VERSION "0.0.12.2"

NS_ :

BS_:

BU_: InstrumentCluster DCU
VAL_TABLE_ DisplayUserInformationTbl 3 "Not Available" 2 "Reserved" 1 "OK" 0 "NOK" ;
VAL_TABLE_ ChargingPortCommandTable 3 "Unknown" 2 "Reserved" 1 "Pressed" 0 "Released" ;
VAL_TABLE_ panicAlertFleetReq_table 3 "NotAvailable" 2 "Reserved" 1 "Panic Alert Requested" 0 "Not requested" ;
VAL_TABLE_ touchpointPanicAlertStatus_Table 3 "Exterior Touchpoints only" 2 "Interior Touchpoints only" 1 "All touchpoints" 0 "No alert" ;
VAL_TABLE_ panicAlertCancelReq_table 3 "NotAvailable" 2 "Reserved" 1 "Panic Alert Canceled" 0 "Not requested" ;
VAL_TABLE_ RouteAssigned_table 3 "Not available" 1 "Assigned" 0 "NotAssigned" ;
VAL_TABLE_ stopRequestStatus_table 10 "Door 3 Open" 9 "Door 2 Open" 8 "Door 1 Open" 7 "Door 3 Requested" 6 "Door 2 Requested" 5 "Door 1 Requested" 4 "Stop Completed" 3 "Stop Reached" 2 "Wheelchair Stop Requested" 1 "Bell Pusher Stop Requested" 0 "Not Requested" ;
VAL_TABLE_ CompressorFrozenStateTable 3 "NA" 1 "FROZEN" 0 "NORMAL" ;
VAL_TABLE_ CompressorState 3 "NA" 1 "ERROR" 0 "OK" ;
VAL_TABLE_ CommLostTable 3 "NA" 1 "Connection lost" 0 "OK" ;
VAL_TABLE_ ParkAssistAuto 3 "Not available" 1 "Requested" 0 "NotRequested" ;
VAL_TABLE_ RouteAssigned 3 "Not available" 1 "Assigned" 0 "NotAssigned" ;
VAL_TABLE_ CHRG_ReqTable 3 "Reserve" 2 "Stop charging" 1 "Immediate charging required" 0 "No request" ;
VAL_TABLE_ vt_TMSPumpControlMode 21 "NA" 2 "ParkMode" 1 "ChargeMode" 0 "DriveMode" ;
VAL_TABLE_ vtHVHeaterTempSP 3 "NA" 2 "TempSP2" 1 "TempSP1" 0 "NA1" ;
VAL_TABLE_ ChargeFaultState 4 "NEVER_ENABLE" 3 "FAULT_DELAY_BEFORE_EN" 2 "IGN_DISABLE" 1 "FAULT_DELAY_BEFORE_DIS" 0 "NO_FAULT" ;
VAL_TABLE_ ChargeOverride 3 "ChargingFault" 2 "ChargeAcOverrideEn" 1 "ChargeChademoOverrideEn" 0 "ChargeOverrideDis" ;
VAL_TABLE_ LvOverideStatus 3 "LvOverrideEn" 2 "LvOverrideEn_5minWait" 1 "LvThrCheckHVSock" 0 "LvOverideDis" ;
VAL_TABLE_ HVHeterPWMCMD_t 15 "NA" 13 "STANDBY1" 12 "OVERHEAT_UNLOCK" 11 "P8" 10 "P7" 9 "P6" 8 "P5" 7 "P4" 6 "P3" 5 "P2" 4 "P1" 3 "TEMP_SP2" 2 "TEMP_SP1" 1 "STANDBY" 0 "OFF" ;
VAL_TABLE_ HVHeaterPWMSTAT_t 15 "NA" 13 "LOCKED_PERM" 12 "LOCKED_OVERHEAT" 11 "LOCKED_TEMPOR" 10 "Ta75_PaSP" 9 "Tb75_PaSP" 8 "Tb40_PaSP" 7 "Tb0_PaSP" 6 "Ta75_PbSP" 5 "Tb75_PbSP" 4 "Tb40_PbSP" 3 "Tb0_PbSP" 2 "SP2" 1 "SP1" 0 "OFF" ;
VAL_TABLE_ HVDrStat_t 11 "ERRCHANGESP" 10 "HV_POWER_PROBLEM" 15 "NA" 9 "ERROR" 8 "FLOWNOTREADY" 7 "LOCKED_PERM" 6 "LOCKED_OVERHEAT" 5 "LOCKED_TEMPOR" 4 "SP_Request" 3 "SP_above" 2 "SP_below" 1 "STANDBY" 0 "OFF" ;
VAL_TABLE_ CabinBlowDirectionTbl 7 "NA" 0 "Reserved" 4 "Take_no_Action" 3 "Down" 2 "Med" 1 "Up" ;
VAL_TABLE_ vAction_t 3 "va_Take_no_action" 2 "va_Reserved" 1 "va_On" 0 "va_Off" ;
VAL_TABLE_ vtEnergyMode 7 "Not Available" 1 "RangeExtender" 0 "PureElectric" ;
VAL_TABLE_ vtOnOff 3 "Not available" 2 "Error" 1 "On" 0 "Off" ;

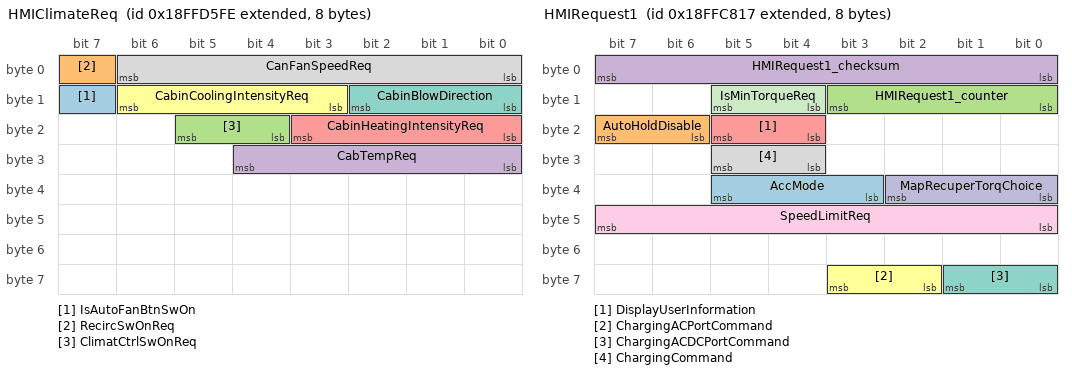
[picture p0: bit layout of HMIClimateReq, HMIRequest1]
BO_ 2566903294 HMIClimateReq: 8 Vector__XXX
 SG_ IsAutoFanBtnSwOn : 15|1@1+ (1,0) [0|0] "" Vector__XXX
 SG_ RecircSwOnReq : 7|1@1+ (1,0) [0|0] "" Vector__XXX
 SG_ ClimatCtrlSwOnReq : 20|2@1+ (1,0) [0|0] "" Vector__XXX
 SG_ CabTempReq : 24|5@1+ (1,0) [0|0] "" Vector__XXX
 SG_ CabinHeatingIntensityReq : 16|4@1+ (1,0) [0|0] "" Vector__XXX
 SG_ CabinCoolingIntensityReq : 11|4@1+ (1,0) [0|0] "" Vector__XXX
 SG_ CabinBlowDirection : 8|3@1+ (1,0) [0|0] "" Vector__XXX
 SG_ CanFanSpeedReq : 0|7@1+ (1,0) [0|0] "" Vector__XXX

BO_ 2381845271 STOPREQ: 8 Vector__XXX
 SG_ stopRequestStatus : 0|4@1+ (1,0) [0|15] "" Vector__XXX

BO_ 2566899735 HMIRequest1: 8 InstrumentCluster
 SG_ AccMode : 35|3@1+ (1,0) [0|7] "" Vector__XXX
 SG_ AutoHoldDisable : 22|2@1+ (1,0) [0|3] "" Vector__XXX
 SG_ HMIRequest1_counter : 8|4@1+ (1,0) [0|14] "" Vector__XXX
 SG_ HMIRequest1_checksum : 0|8@1+ (1,0) [0|255] "" Vector__XXX
 SG_ DisplayUserInformation : 20|2@1+ (1,0) [0|3] "" Vector__XXX
 SG_ ChargingACPortCommand : 58|2@1+ (1,0) [0|3] "" Vector__XXX
 SG_ ChargingACDCPortCommand : 56|2@1+ (1,0) [0|3] "" Vector__XXX
 SG_ ChargingCommand : 28|2@1+ (1,0) [0|3] "" Vector__XXX
 SG_ SpeedLimitReq : 40|8@1+ (1,0) [0|0] "kph" Vector__XXX
 SG_ MapRecuperTorqChoice : 32|3@1+ (1,0) [0|0] "" Vector__XXX
 SG_ IsMinTorqueReq : 12|2@1+ (1,0) [0|3] "" Vector__XXX

BO_ 2583184638 HMIPlatform_Info: 8 Vector__XXX
 SG_ ManualLevelling_Value : 0|8@1+ (1,0) [0|100] "" Vector__XXX

CM_ BO_ 2566899735 "DataID 0xFC8";
CM_ SG_ 2566899735 HMIRequest1_counter "counter signal for E2E protection";
CM_ SG_ 2566899735 HMIRequest1_checksum "Checksum signal for E2E protection";
CM_ SG_ 2566899735 MapRecuperTorqChoice "Choice of recuperation torque map:1,2,3... - select # of Map";
CM_ SG_ 2566899735 IsMinTorqueReq "Define Is minimal torque required when pedal is not depressed";
CM_ BO_ 2583184638 "The message contains the manual request for headlamps height  from HMI
HDLGHTLVL 1.0.0->ManualLevellingHeadlamps";
BA_DEF_  "DBName" STRING ;
BA_DEF_ SG_  "SigType" ENUM  "Default","Range","RangeSigned","ASCII","Discrete","Control","ReferencePGN","DTC","StringDelimiter","StringLength","StringLengthControl","MessageCounter","MessageChecksum";
BA_DEF_ SG_  "GenSigStartValue" INT 0 2147483647;
BA_DEF_ SG_  "GenSigSendType" ENUM  "Cyclic","OnWrite","OnWriteWithRepetition","OnChange","OnChangeWithRepetition","IfActive","IfActiveWithRepetition","NoSigSendType";
BA_DEF_ SG_  "GenSigILSupport" ENUM  "No","Yes";
BA_DEF_ SG_  "GenSigEVName" STRING ;
BA_DEF_ BO_  "GenMsgILSupport" ENUM  "No","Yes";
BA_DEF_ BO_  "GenMsgRequestable" INT 0 1;
BA_DEF_ BO_  "GenMsgSendType" ENUM  "cyclic","NotUsed","NotUsed","NotUsed","NotUsed","NotUsed","NotUsed","IfActive","noMsgSendType";
BA_DEF_ BO_  "VFrameFormat" ENUM  "StandardCAN","ExtendedCAN","reserved","J1939PG";
BA_DEF_ BO_  "GenMsgCycleTime" INT 0 3600000;
BA_DEF_ BU_  "NmStationAddress" INT 0 255;
BA_DEF_  "SAE_J1939_DA_SpecVersion" STRING ;
BA_DEF_  "SAE_J1939_81_SpecVersion" STRING ;
BA_DEF_  "DatabaseVersion" STRING ;
BA_DEF_  "BusType" STRING ;
BA_DEF_  "ProtocolType" STRING ;
BA_DEF_  "SAE_J1939_75_SpecVersion" STRING ;
BA_DEF_  "SAE_J1939_21_SpecVersion" STRING ;
BA_DEF_  "SAE_J1939_73_SpecVersion" STRING ;
BA_DEF_  "SAE_J1939_71_SpecVersion" STRING ;
BA_DEF_DEF_  "DBName" "";
BA_DEF_DEF_  "SigType" "Default";
BA_DEF_DEF_  "GenSigStartValue" 0;
BA_DEF_DEF_  "GenSigSendType" "NoSigSendType";
BA_DEF_DEF_  "GenSigILSupport" "Yes";
BA_DEF_DEF_  "GenSigEVName" "Env@Nodename_@Signame";
BA_DEF_DEF_  "GenMsgILSupport" "Yes";
BA_DEF_DEF_  "GenMsgRequestable" 1;
BA_DEF_DEF_  "GenMsgSendType" "noMsgSendType";
BA_DEF_DEF_  "VFrameFormat" "J1939PG";
BA_DEF_DEF_  "GenMsgCycleTime" 0;
BA_DEF_DEF_  "NmStationAddress" 254;
BA_DEF_DEF_  "SAE_J1939_DA_SpecVersion" "";
BA_DEF_DEF_  "SAE_J1939_81_SpecVersion" "";
BA_DEF_DEF_  "DatabaseVersion" "";
BA_DEF_DEF_  "BusType" "";
BA_DEF_DEF_  "ProtocolType" "";
BA_DEF_DEF_  "SAE_J1939_75_SpecVersion" "";
BA_DEF_DEF_  "SAE_J1939_21_SpecVersion" "";
BA_DEF_DEF_  "SAE_J1939_73_SpecVersion" "";
BA_DEF_DEF_  "SAE_J1939_71_SpecVersion" "";
BA_ "SAE_J1939_DA_SpecVersion" "2015-01";
BA_ "SAE_J1939_81_SpecVersion" "2012-05";
BA_ "DatabaseVersion" "8.5";
BA_ "BusType" "CAN";
BA_ "ProtocolType" "J1939";
BA_ "SAE_J1939_75_SpecVersion" "2012-05";
BA_ "SAE_J1939_21_SpecVersion" "2006-10";
BA_ "SAE_J1939_73_SpecVersion" "2012-10";
BA_ "SAE_J1939_71_SpecVersion" "2012-10";
BA_ "DBName" "Arrival_DCU_P2";
BA_ "NmStationAddress" BU_ InstrumentCluster 23;
BA_ "NmStationAddress" BU_ DCU 90;
BA_ "GenMsgCycleTime" BO_ 2566903294 250;
BA_ "GenMsgSendType" BO_ 2381845271 0;
BA_ "GenMsgCycleTime" BO_ 2381845271 100;
BA_ "GenMsgCycleTime" BO_ 2566899735 100;
BA_ "GenMsgSendType" BO_ 2566899735 0;
BA_ "GenMsgSendType" BO_ 2583184638 0;
BA_ "GenMsgCycleTime" BO_ 2583184638 1000;
BA_ "GenSigStartValue" SG_ 2566899735 AccMode 1;
BA_ "GenSigStartValue" SG_ 2566899735 AutoHoldDisable 1;
BA_ "SigType" SG_ 2566899735 HMIRequest1_counter 11;
BA_ "SigType" SG_ 2566899735 HMIRequest1_checksum 12;
BA_ "GenSigStartValue" SG_ 2566899735 DisplayUserInformation 3;
BA_ "GenSigStartValue" SG_ 2566899735 ChargingACPortCommand 3;
BA_ "GenSigStartValue" SG_ 2566899735 ChargingACDCPortCommand 3;
BA_ "GenSigStartValue" SG_ 2566899735 SpeedLimitReq 100;
BA_ "GenSigStartValue" SG_ 2583184638 ManualLevelling_Value 50;
VAL_ 2566903294 ClimatCtrlSwOnReq 3 "va_Take_no_action" 2 "va_Reserved" 1 "va_On" 0 "va_off" ;
VAL_ 2566903294 CabinBlowDirection 7 "NA" 4 "Take_no_Action" 3 "Down" 2 "Med" 1 "Up" 0 "Reserved" ;
VAL_ 2381845271 stopRequestStatus 10 "Door 3 Open" 9 "Door 2 Open" 8 "Door 1 Open" 7 "Door 3 Requested" 6 "Door 2 Requested" 5 "Door 1 Requested" 4 "Stop Completed" 3 "Stop Reached" 2 "Wheelchair Stop Requested" 1 "Bell Pusher Stop Requested" 0 "Not Requested" ;
VAL_ 2566899735 AccMode 7 "NA" 4 "accMode4" 3 "accMode3" 2 "accMode2" 1 "accMode1" ;
VAL_ 2566899735 AutoHoldDisable 3 "NotAvailable" 2 "Fault" 1 "Enabled" 0 "Disabled" ;
VAL_ 2566899735 DisplayUserInformation 3 "Not Available" 2 "Reserved" 1 "OK" 0 "NOK" ;
VAL_ 2566899735 ChargingACPortCommand 3 "Unknown" 2 "Reserved" 1 "Pressed" 0 "Released" ;
VAL_ 2566899735 ChargingACDCPortCommand 3 "Unknown" 2 "Reserved" 1 "Pressed" 0 "Released" ;
VAL_ 2566899735 ChargingCommand 3 "Reserve" 2 "Stop charging" 1 "Immediate charging required" 0 "No request" ;
VAL_ 2566899735 MapRecuperTorqChoice 0 "NA" 3 "Map3" 2 "Map2" 1 "Map1" ;
VAL_ 2566899735 IsMinTorqueReq 3 "Not available" 2 "Error" 1 "On" 0 "Off" ;
